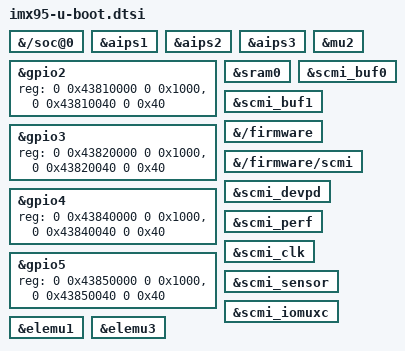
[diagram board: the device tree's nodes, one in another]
// SPDX-License-Identifier: GPL-2.0-or-later OR MIT

&{/soc@0} {
	bootph-all;
};

&aips1 {
	bootph-all;
};

&aips2 {
	bootph-all;
};

&aips3 {
	bootph-all;
};

&gpio2 {
	reg = <0 0x43810000 0 0x1000>, <0 0x43810040 0 0x40>;
	bootph-all;
};

&gpio3 {
	reg = <0 0x43820000 0 0x1000>, <0 0x43820040 0 0x40>;
	bootph-all;
};

&gpio4 {
	reg = <0 0x43840000 0 0x1000>, <0 0x43840040 0 0x40>;
	bootph-all;
};

&gpio5 {
	reg = <0 0x43850000 0 0x1000>, <0 0x43850040 0 0x40>;
	bootph-all;
};

&mu2 {
	bootph-all;
};

&sram0 {
	bootph-all;
};

&scmi_buf0 {
	bootph-all;
};

&scmi_buf1 {
	bootph-all;
};

&{/firmware} {
	bootph-all;
};

&{/firmware/scmi} {
	bootph-all;
};

&scmi_devpd {
	bootph-all;
};

&scmi_perf {
	bootph-all;
};

&scmi_clk {
	bootph-all;
};

&scmi_sensor {
	bootph-all;
};

&scmi_iomuxc {
	bootph-all;
};

&elemu1 {
	bootph-all;
	status = "okay";
};

&elemu3 {
	bootph-all;
	status = "okay";
};
